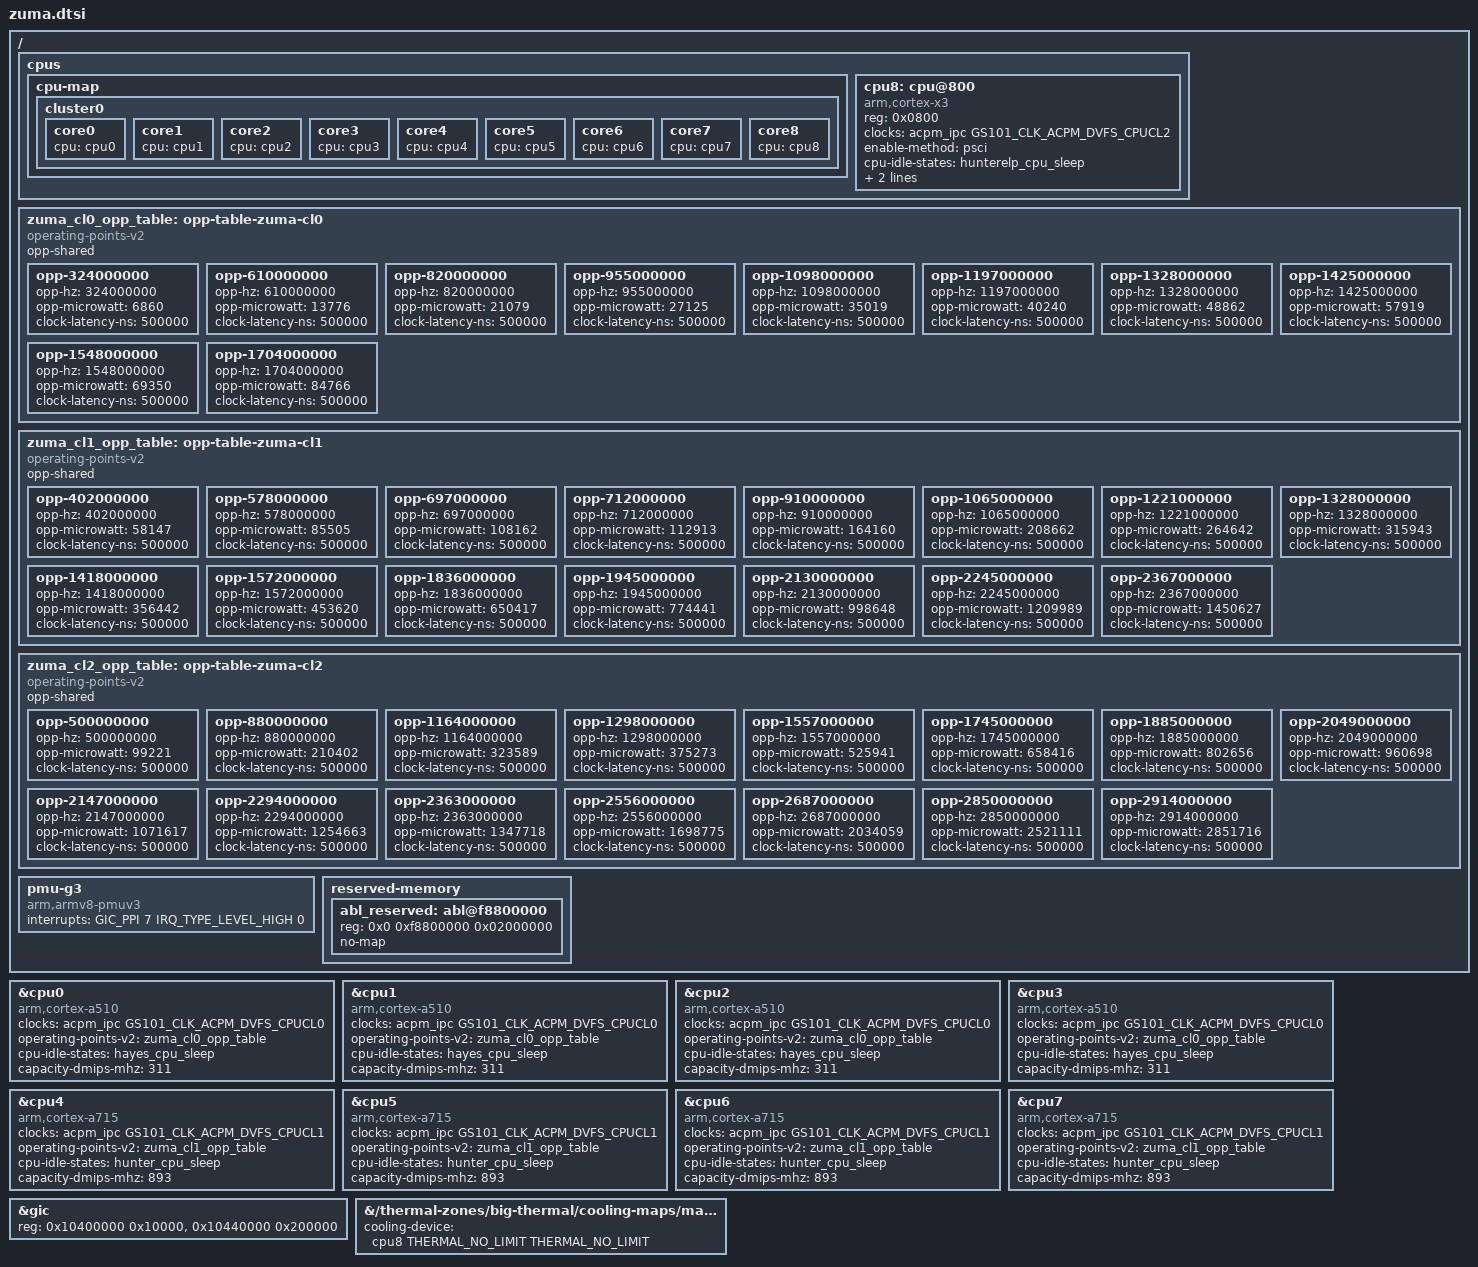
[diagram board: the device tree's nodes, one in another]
// SPDX-License-Identifier: GPL-2.0-only
/*
 * Google Tensor G3 (zuma) SoC, described as deltas on Tensor G4 (zumapro).
 *
 * Google's own downstream trees show how close the two are: of 572 SoC nodes
 * in kernel/devices/google/zuma (android-gs-shusky-6.1-android16) and
 * kernel/devices/google/zumapro (android-gs-caimito-6.1-android16), 567 share
 * name and unit address; interrupt numbers (dt-bindings zuma.h vs zumapro.h)
 * do not differ in value; and the caimito kernel drives its clocks from the
 * very same cal-if/zuma tables as shusky. So everything below is what the G3
 * really does differently:
 *
 *  - 9 CPUs in one DSU cluster (4x Cortex-A510, 4x Cortex-A715, 1x Cortex-X3)
 *    instead of 8 (MPIDR 0x000..0x800, as downstream zuma-cpu.dtsi);
 *  - so the GIC redistributor region covers 9 frames (downstream: 0x200000);
 *  - one PMU interrupt for all cores, as downstream (no PPI partitions);
 *  - the bootloader's own carveout at 0xf8800000.
 *
 * CPU DVFS: the ACPM DVFS domain numbering is the same (CPUCL0/1/2 = 2/3/4,
 * downstream cal-if/zuma acpm_dvfs_zuma.h), but the G3 has its own tables.
 * Frequencies and power (opp-microwatt) were read from a running husky's
 * stock kernel (cpufreq policies and debugfs energy_model, Evolution X 17 /
 * CP2A.260805.005); capacity-dmips-mhz reproduces its cpu_capacity of
 * 182/725/1024 at the clusters' top frequencies. Idle states keep zumapro's
 * PSCI parameters, which match downstream zuma-cpu.dtsi (klein/makalu/
 * makaluelp: 70+160, 150+190, 235+220 us).
 */

#include "zumapro.dtsi"

/ {
	cpus {
		/delete-node/ cpu-map;

		cpu-map {
			cluster0 {
				core0 { cpu = <&cpu0>; };
				core1 { cpu = <&cpu1>; };
				core2 { cpu = <&cpu2>; };
				core3 { cpu = <&cpu3>; };
				core4 { cpu = <&cpu4>; };
				core5 { cpu = <&cpu5>; };
				core6 { cpu = <&cpu6>; };
				core7 { cpu = <&cpu7>; };
				core8 { cpu = <&cpu8>; };
			};
		};

		cpu8: cpu@800 {
			#cooling-cells = <2>;
			device_type = "cpu";
			compatible = "arm,cortex-x3";
			reg = <0x0800>;
			clocks = <&acpm_ipc GS101_CLK_ACPM_DVFS_CPUCL2>;
			enable-method = "psci";
			cpu-idle-states = <&hunterelp_cpu_sleep>;
			capacity-dmips-mhz = <1024>;
			operating-points-v2 = <&zuma_cl2_opp_table>;
		};
	};

	/delete-node/ pmu-0;
	/delete-node/ pmu-1;
	/delete-node/ pmu-2;

	/delete-node/ opp-table-0;
	/delete-node/ opp-table-1;
	/delete-node/ opp-table-2;

	zuma_cl0_opp_table: opp-table-zuma-cl0 {
		compatible = "operating-points-v2";
		opp-shared;

		opp-324000000 {
			opp-hz = /bits/ 64 <324000000>;
			opp-microwatt = <6860>;
			clock-latency-ns = <500000>;
		};

		opp-610000000 {
			opp-hz = /bits/ 64 <610000000>;
			opp-microwatt = <13776>;
			clock-latency-ns = <500000>;
		};

		opp-820000000 {
			opp-hz = /bits/ 64 <820000000>;
			opp-microwatt = <21079>;
			clock-latency-ns = <500000>;
		};

		opp-955000000 {
			opp-hz = /bits/ 64 <955000000>;
			opp-microwatt = <27125>;
			clock-latency-ns = <500000>;
		};

		opp-1098000000 {
			opp-hz = /bits/ 64 <1098000000>;
			opp-microwatt = <35019>;
			clock-latency-ns = <500000>;
		};

		opp-1197000000 {
			opp-hz = /bits/ 64 <1197000000>;
			opp-microwatt = <40240>;
			clock-latency-ns = <500000>;
		};

		opp-1328000000 {
			opp-hz = /bits/ 64 <1328000000>;
			opp-microwatt = <48862>;
			clock-latency-ns = <500000>;
		};

		opp-1425000000 {
			opp-hz = /bits/ 64 <1425000000>;
			opp-microwatt = <57919>;
			clock-latency-ns = <500000>;
		};

		opp-1548000000 {
			opp-hz = /bits/ 64 <1548000000>;
			opp-microwatt = <69350>;
			clock-latency-ns = <500000>;
		};

		opp-1704000000 {
			opp-hz = /bits/ 64 <1704000000>;
			opp-microwatt = <84766>;
			clock-latency-ns = <500000>;
		};
	};

	zuma_cl1_opp_table: opp-table-zuma-cl1 {
		compatible = "operating-points-v2";
		opp-shared;

		opp-402000000 {
			opp-hz = /bits/ 64 <402000000>;
			opp-microwatt = <58147>;
			clock-latency-ns = <500000>;
		};

		opp-578000000 {
			opp-hz = /bits/ 64 <578000000>;
			opp-microwatt = <85505>;
			clock-latency-ns = <500000>;
		};

		opp-697000000 {
			opp-hz = /bits/ 64 <697000000>;
			opp-microwatt = <108162>;
			clock-latency-ns = <500000>;
		};

		opp-712000000 {
			opp-hz = /bits/ 64 <712000000>;
			opp-microwatt = <112913>;
			clock-latency-ns = <500000>;
		};

		opp-910000000 {
			opp-hz = /bits/ 64 <910000000>;
			opp-microwatt = <164160>;
			clock-latency-ns = <500000>;
		};

		opp-1065000000 {
			opp-hz = /bits/ 64 <1065000000>;
			opp-microwatt = <208662>;
			clock-latency-ns = <500000>;
		};

		opp-1221000000 {
			opp-hz = /bits/ 64 <1221000000>;
			opp-microwatt = <264642>;
			clock-latency-ns = <500000>;
		};

		opp-1328000000 {
			opp-hz = /bits/ 64 <1328000000>;
			opp-microwatt = <315943>;
			clock-latency-ns = <500000>;
		};

		opp-1418000000 {
			opp-hz = /bits/ 64 <1418000000>;
			opp-microwatt = <356442>;
			clock-latency-ns = <500000>;
		};

		opp-1572000000 {
			opp-hz = /bits/ 64 <1572000000>;
			opp-microwatt = <453620>;
			clock-latency-ns = <500000>;
		};

		opp-1836000000 {
			opp-hz = /bits/ 64 <1836000000>;
			opp-microwatt = <650417>;
			clock-latency-ns = <500000>;
		};

		opp-1945000000 {
			opp-hz = /bits/ 64 <1945000000>;
			opp-microwatt = <774441>;
			clock-latency-ns = <500000>;
		};

		opp-2130000000 {
			opp-hz = /bits/ 64 <2130000000>;
			opp-microwatt = <998648>;
			clock-latency-ns = <500000>;
		};

		opp-2245000000 {
			opp-hz = /bits/ 64 <2245000000>;
			opp-microwatt = <1209989>;
			clock-latency-ns = <500000>;
		};

		opp-2367000000 {
			opp-hz = /bits/ 64 <2367000000>;
			opp-microwatt = <1450627>;
			clock-latency-ns = <500000>;
		};
	};

	zuma_cl2_opp_table: opp-table-zuma-cl2 {
		compatible = "operating-points-v2";
		opp-shared;

		opp-500000000 {
			opp-hz = /bits/ 64 <500000000>;
			opp-microwatt = <99221>;
			clock-latency-ns = <500000>;
		};

		opp-880000000 {
			opp-hz = /bits/ 64 <880000000>;
			opp-microwatt = <210402>;
			clock-latency-ns = <500000>;
		};

		opp-1164000000 {
			opp-hz = /bits/ 64 <1164000000>;
			opp-microwatt = <323589>;
			clock-latency-ns = <500000>;
		};

		opp-1298000000 {
			opp-hz = /bits/ 64 <1298000000>;
			opp-microwatt = <375273>;
			clock-latency-ns = <500000>;
		};

		opp-1557000000 {
			opp-hz = /bits/ 64 <1557000000>;
			opp-microwatt = <525941>;
			clock-latency-ns = <500000>;
		};

		opp-1745000000 {
			opp-hz = /bits/ 64 <1745000000>;
			opp-microwatt = <658416>;
			clock-latency-ns = <500000>;
		};

		opp-1885000000 {
			opp-hz = /bits/ 64 <1885000000>;
			opp-microwatt = <802656>;
			clock-latency-ns = <500000>;
		};

		opp-2049000000 {
			opp-hz = /bits/ 64 <2049000000>;
			opp-microwatt = <960698>;
			clock-latency-ns = <500000>;
		};

		opp-2147000000 {
			opp-hz = /bits/ 64 <2147000000>;
			opp-microwatt = <1071617>;
			clock-latency-ns = <500000>;
		};

		opp-2294000000 {
			opp-hz = /bits/ 64 <2294000000>;
			opp-microwatt = <1254663>;
			clock-latency-ns = <500000>;
		};

		opp-2363000000 {
			opp-hz = /bits/ 64 <2363000000>;
			opp-microwatt = <1347718>;
			clock-latency-ns = <500000>;
		};

		opp-2556000000 {
			opp-hz = /bits/ 64 <2556000000>;
			opp-microwatt = <1698775>;
			clock-latency-ns = <500000>;
		};

		opp-2687000000 {
			opp-hz = /bits/ 64 <2687000000>;
			opp-microwatt = <2034059>;
			clock-latency-ns = <500000>;
		};

		opp-2850000000 {
			opp-hz = /bits/ 64 <2850000000>;
			opp-microwatt = <2521111>;
			clock-latency-ns = <500000>;
		};

		opp-2914000000 {
			opp-hz = /bits/ 64 <2914000000>;
			opp-microwatt = <2851716>;
			clock-latency-ns = <500000>;
		};
	};

	pmu-g3 {
		compatible = "arm,armv8-pmuv3";
		interrupts = <GIC_PPI 7 IRQ_TYPE_LEVEL_HIGH 0>;
	};

	reserved-memory {
		abl_reserved: abl@f8800000 {
			reg = <0x0 0xf8800000 0x02000000>;
			no-map;
		};
	};
};

&cpu0 {
	compatible = "arm,cortex-a510";
	clocks = <&acpm_ipc GS101_CLK_ACPM_DVFS_CPUCL0>;
	operating-points-v2 = <&zuma_cl0_opp_table>;
	cpu-idle-states = <&hayes_cpu_sleep>;
	/delete-property/ dynamic-power-coefficient;
	capacity-dmips-mhz = <311>;
};

&cpu1 {
	compatible = "arm,cortex-a510";
	clocks = <&acpm_ipc GS101_CLK_ACPM_DVFS_CPUCL0>;
	operating-points-v2 = <&zuma_cl0_opp_table>;
	cpu-idle-states = <&hayes_cpu_sleep>;
	/delete-property/ dynamic-power-coefficient;
	capacity-dmips-mhz = <311>;
};

&cpu2 {
	compatible = "arm,cortex-a510";
	clocks = <&acpm_ipc GS101_CLK_ACPM_DVFS_CPUCL0>;
	operating-points-v2 = <&zuma_cl0_opp_table>;
	cpu-idle-states = <&hayes_cpu_sleep>;
	/delete-property/ dynamic-power-coefficient;
	capacity-dmips-mhz = <311>;
};

&cpu3 {
	compatible = "arm,cortex-a510";
	clocks = <&acpm_ipc GS101_CLK_ACPM_DVFS_CPUCL0>;
	operating-points-v2 = <&zuma_cl0_opp_table>;
	cpu-idle-states = <&hayes_cpu_sleep>;
	/delete-property/ dynamic-power-coefficient;
	capacity-dmips-mhz = <311>;
};

&cpu4 {
	compatible = "arm,cortex-a715";
	clocks = <&acpm_ipc GS101_CLK_ACPM_DVFS_CPUCL1>;
	operating-points-v2 = <&zuma_cl1_opp_table>;
	cpu-idle-states = <&hunter_cpu_sleep>;
	/delete-property/ dynamic-power-coefficient;
	capacity-dmips-mhz = <893>;
};

&cpu5 {
	compatible = "arm,cortex-a715";
	clocks = <&acpm_ipc GS101_CLK_ACPM_DVFS_CPUCL1>;
	operating-points-v2 = <&zuma_cl1_opp_table>;
	cpu-idle-states = <&hunter_cpu_sleep>;
	/delete-property/ dynamic-power-coefficient;
	capacity-dmips-mhz = <893>;
};

&cpu6 {
	compatible = "arm,cortex-a715";
	clocks = <&acpm_ipc GS101_CLK_ACPM_DVFS_CPUCL1>;
	operating-points-v2 = <&zuma_cl1_opp_table>;
	cpu-idle-states = <&hunter_cpu_sleep>;
	/delete-property/ dynamic-power-coefficient;
	capacity-dmips-mhz = <893>;
};

&cpu7 {
	compatible = "arm,cortex-a715";
	clocks = <&acpm_ipc GS101_CLK_ACPM_DVFS_CPUCL1>;
	operating-points-v2 = <&zuma_cl1_opp_table>;
	cpu-idle-states = <&hunter_cpu_sleep>;
	/delete-property/ dynamic-power-coefficient;
	capacity-dmips-mhz = <893>;
};

&gic {
	reg = <0x10400000 0x10000>,	/* GICD */
	      <0x10440000 0x200000>;	/* GICR, 9 frames (downstream size) */

	/delete-node/ ppi-partitions;
};

/*
 * On the G4 the big core is cpu7; on the G3 it is cpu8 (cpu7 is an A715).
 * Left as is, the big zone throttled the A715 cluster while the X3 ran on at
 * 2.9 GHz up to 109 C (seen under a 9-core busy loop).
 */
&{/thermal-zones/big-thermal/cooling-maps/map0} {
	cooling-device = <&cpu8 THERMAL_NO_LIMIT THERMAL_NO_LIMIT>;
};
